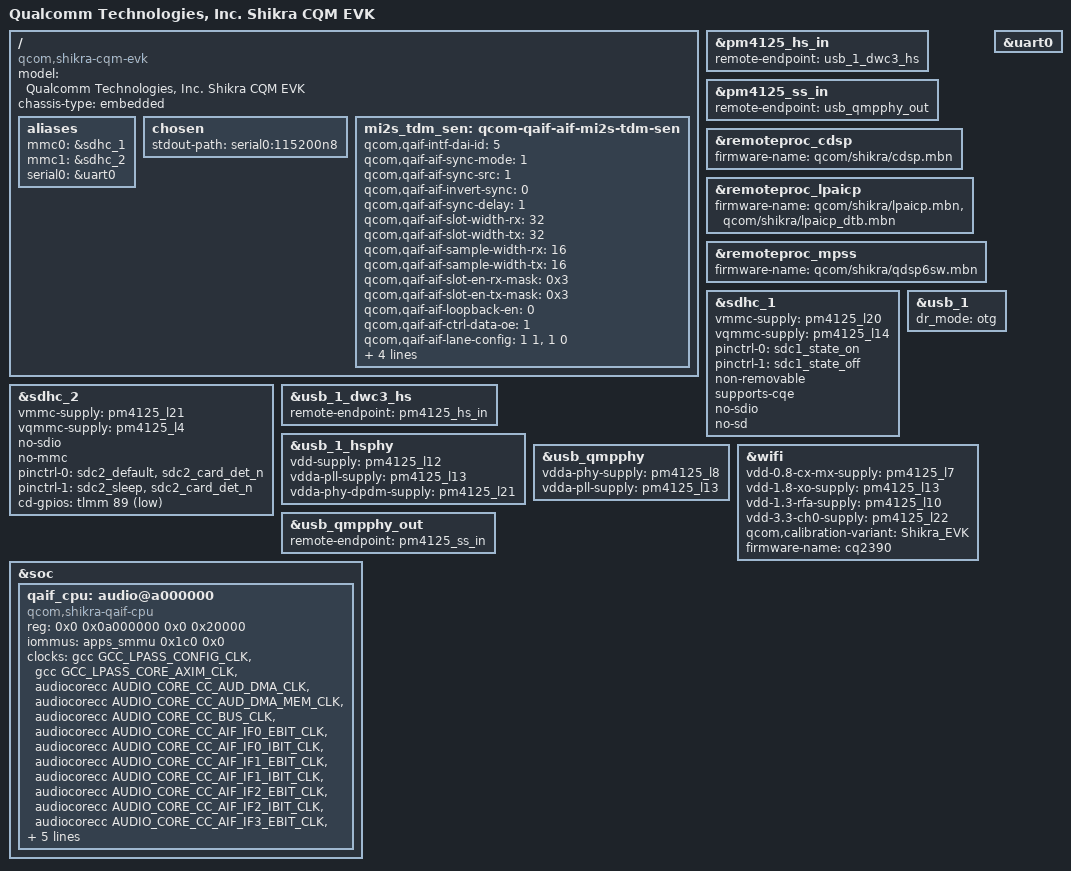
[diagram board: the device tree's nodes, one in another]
// SPDX-License-Identifier: BSD-3-Clause
/*
 * Copyright (c) Qualcomm Technologies, Inc. and/or its subsidiaries.
 */

/dts-v1/;

#include "shikra-cqm-som.dtsi"
#include "shikra-evk.dtsi"
#include <dt-bindings/gpio/gpio.h>
#include <dt-bindings/sound/qcom,lpass.h>

/ {
	model = "Qualcomm Technologies, Inc. Shikra CQM EVK";
	compatible = "qcom,shikra-cqm-evk", "qcom,shikra-cqm-som", "qcom,shikra";
	chassis-type = "embedded";

	aliases {
		mmc0 = &sdhc_1;
		mmc1 = &sdhc_2; /* SDC2 SD card slot */
		serial0 = &uart0;
	};

	chosen {
		stdout-path = "serial0:115200n8";
	};
};

&pm4125_hs_in {
	remote-endpoint = <&usb_1_dwc3_hs>;
};

&pm4125_ss_in {
	remote-endpoint = <&usb_qmpphy_out>;
};

&remoteproc_cdsp {
	firmware-name = "qcom/shikra/cdsp.mbn";

	status = "okay";
};

&remoteproc_lpaicp {
	firmware-name = "qcom/shikra/lpaicp.mbn",
			"qcom/shikra/lpaicp_dtb.mbn";

	status = "okay";
};

&remoteproc_mpss {
	firmware-name = "qcom/shikra/qdsp6sw.mbn";

	status = "okay";
};

&sdhc_1 {
	vmmc-supply = <&pm4125_l20>;
	vqmmc-supply = <&pm4125_l14>;

	pinctrl-0 = <&sdc1_state_on>;
	pinctrl-1 = <&sdc1_state_off>;
	pinctrl-names = "default", "sleep";

	non-removable;
	supports-cqe;
	no-sdio;
	no-sd;

	status = "okay";
};

&sdhc_2 {
	vmmc-supply = <&pm4125_l21>;
	vqmmc-supply = <&pm4125_l4>;

	no-sdio;
	no-mmc;

	pinctrl-0 = <&sdc2_default &sdc2_card_det_n>;
	pinctrl-1 = <&sdc2_sleep &sdc2_card_det_n>;
	pinctrl-names = "default", "sleep";

	cd-gpios = <&tlmm 89 GPIO_ACTIVE_LOW>;

	status = "okay";
};

&uart0 {
	status = "okay";
};

&usb_1 {
	dr_mode = "otg";

	status = "okay";
};

&usb_1_dwc3_hs {
	remote-endpoint = <&pm4125_hs_in>;
};

&usb_1_hsphy {
	vdd-supply = <&pm4125_l12>;
	vdda-pll-supply = <&pm4125_l13>;
	vdda-phy-dpdm-supply = <&pm4125_l21>;

	status = "okay";
};

&usb_qmpphy {
	vdda-phy-supply = <&pm4125_l8>;
	vdda-pll-supply = <&pm4125_l13>;

	status = "okay";
};

&wifi {
	vdd-0.8-cx-mx-supply = <&pm4125_l7>;
	vdd-1.8-xo-supply = <&pm4125_l13>;
	vdd-1.3-rfa-supply = <&pm4125_l10>;
	vdd-3.3-ch0-supply = <&pm4125_l22>;
	qcom,calibration-variant = "Shikra_EVK";
	firmware-name = "cq2390";

	status = "okay";
};

&usb_qmpphy_out {
	remote-endpoint = <&pm4125_ss_in>;
};

/ {
	mi2s_tdm_sen: qcom-qaif-aif-mi2s-tdm-sen {
		qcom,qaif-intf-dai-id = <5>;
		qcom,qaif-aif-sync-mode = <1>;
		qcom,qaif-aif-sync-src = <1>;
		qcom,qaif-aif-invert-sync = <0>;
		qcom,qaif-aif-sync-delay = <1>;
		qcom,qaif-aif-slot-width-rx = <32>;
		qcom,qaif-aif-slot-width-tx = <32>;
		qcom,qaif-aif-sample-width-rx = <16>;
		qcom,qaif-aif-sample-width-tx = <16>;
		qcom,qaif-aif-slot-en-rx-mask = <0x3>;
		qcom,qaif-aif-slot-en-tx-mask = <0x3>;
		qcom,qaif-aif-loopback-en = <0>;
		qcom,qaif-aif-ctrl-data-oe = <1>;
		qcom,qaif-aif-lane-config = <1 1>, <1 0>;
		qcom,qaif-aif-mono-mode-tx = <0>;
		qcom,qaif-aif-mono-mode-rx = <0>;
		qcom,qaif-aif-full-cycle-en = <0>;
		qcom,qaif-aif-bits-per-lane = <2>;
	};
};

&soc {
	qaif_cpu: audio@a000000 {
		compatible = "qcom,shikra-qaif-cpu";
		reg = <0x0 0x0a000000 0x0 0x20000>;
		reg-names = "audio-qaif-core";
		iommus = <&apps_smmu 0x1c0 0x0>;
		clocks = <&gcc GCC_LPASS_CONFIG_CLK>,
			 <&gcc GCC_LPASS_CORE_AXIM_CLK>,
			 <&audiocorecc AUDIO_CORE_CC_AUD_DMA_CLK>,
			 <&audiocorecc AUDIO_CORE_CC_AUD_DMA_MEM_CLK>,
			 <&audiocorecc AUDIO_CORE_CC_BUS_CLK>,
			 <&audiocorecc AUDIO_CORE_CC_AIF_IF0_EBIT_CLK>,
			 <&audiocorecc AUDIO_CORE_CC_AIF_IF0_IBIT_CLK>,
			 <&audiocorecc AUDIO_CORE_CC_AIF_IF1_EBIT_CLK>,
			 <&audiocorecc AUDIO_CORE_CC_AIF_IF1_IBIT_CLK>,
			 <&audiocorecc AUDIO_CORE_CC_AIF_IF2_EBIT_CLK>,
			 <&audiocorecc AUDIO_CORE_CC_AIF_IF2_IBIT_CLK>,
			 <&audiocorecc AUDIO_CORE_CC_AIF_IF3_EBIT_CLK>,
			 <&audiocorecc AUDIO_CORE_CC_AIF_IF3_IBIT_CLK>,
			 <&audiocorecc AUDIO_CORE_CC_EXT_MCLKA_OUT_CLK>,
			 <&audiocorecc AUDIO_CORE_CC_EXT_MCLKB_OUT_CLK>;
		clock-names = "gcc_lpass_config_clk",
			      "gcc_lpass_core_axim_clk",
			      "audio_core_cc_aud_dma_clk",
			      "audio_core_cc_aud_dma_mem_clk",
			      "audio_core_cc_bus_clk",
			      "audio_core_cc_aif_if0_ebit_clk",
			      "audio_core_cc_aif_if0_ibit_clk",
			      "audio_core_cc_aif_if1_ebit_clk",
			      "audio_core_cc_aif_if1_ibit_clk",
			      "audio_core_cc_aif_if2_ebit_clk",
			      "audio_core_cc_aif_if2_ibit_clk",
			      "audio_core_cc_aif_if3_ebit_clk",
			      "audio_core_cc_aif_if3_ibit_clk",
			      "audio_core_cc_ext_mclka_clk",
			      "audio_core_cc_ext_mclkb_clk";
		#sound-dai-cells = <1>;
		#address-cells = <1>;
		#size-cells = <0>;
		interrupts = <GIC_SPI 331 IRQ_TYPE_LEVEL_HIGH>;
		interrupt-names = "qaif-irq-audio-core";
		aif-interface = <&mi2s_tdm_sen>;
		status = "okay";
	};
};
